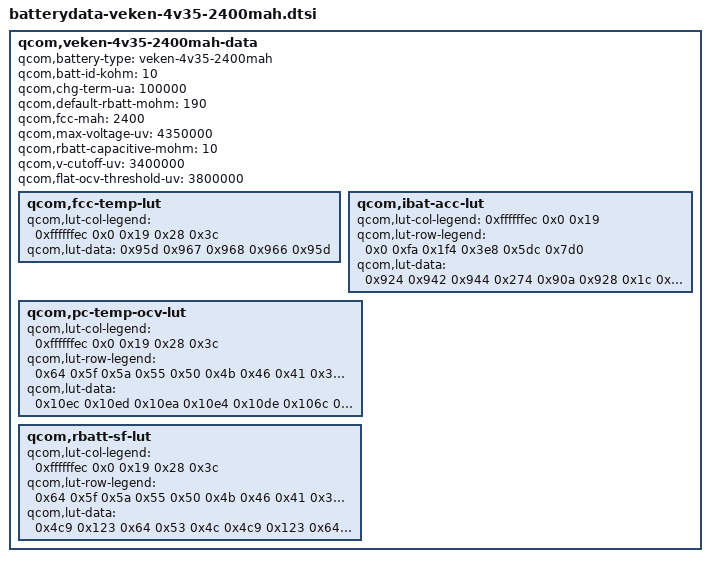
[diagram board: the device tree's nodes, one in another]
/* Copyright (c) 2013, The Linux Foundation. All rights reserved.
 *
 * This program is free software; you can redistribute it and/or modify
 * it under the terms of the GNU General Public License version 2 and
 * only version 2 as published by the Free Software Foundation.
 *
 * This program is distributed in the hope that it will be useful,
 * but WITHOUT ANY WARRANTY; without even the implied warranty of
 * MERCHANTABILITY or FITNESS FOR A PARTICULAR PURPOSE.  See the
 * GNU General Public License for more details.
 */

qcom,veken-4v35-2400mah-data {
	qcom,battery-type = "veken-4v35-2400mah";
	qcom,batt-id-kohm = <10>;
	qcom,chg-term-ua = <100000>;
	qcom,default-rbatt-mohm = <190>;
	qcom,fcc-mah = <2400>;
	qcom,max-voltage-uv = <4350000>;
	qcom,rbatt-capacitive-mohm = <10>;
	qcom,v-cutoff-uv = <3400000>;
	qcom,flat-ocv-threshold-uv = <3800000>;

	qcom,fcc-temp-lut {
		qcom,lut-col-legend = <0xffffffec 0x0 0x19 0x28 0x3c>;
		qcom,lut-data = <0x95d 0x967 0x968 0x966 0x95d>;
	};

	qcom,ibat-acc-lut {
		qcom,lut-col-legend = <0xffffffec 0x0 0x19>;
		qcom,lut-row-legend = <0x0 0xfa 0x1f4 0x3e8 0x5dc 0x7d0>;
		qcom,lut-data = <0x924 0x942 0x944 0x274 0x90a 0x928 0x1c 0x824 0x914 0x2 0x4bc 0x8d7 0x0 0x2c2 0x7f0 0x1 0x196 0x600>;
	};

	qcom,pc-temp-ocv-lut {
		qcom,lut-col-legend = <0xffffffec 0x0 0x19 0x28 0x3c>;
		qcom,lut-row-legend = <0x64 0x5f 0x5a 0x55 0x50 0x4b 0x46 0x41 0x3c 0x37 0x32 0x2d 0x28 0x23 0x1e 0x19 0x14 0x10 0xd 0xb 0xa 0x9 0x8 0x7 0x6 0x5 0x4 0x3 0x2 0x1 0x0>;
		qcom,lut-data = <0x10ec 0x10ed 0x10ea 0x10e4 0x10de 0x106c 0x109a 0x10a4 0x10a2 0x109e 0x1022 0x105d 0x106a 0x106a 0x1066 0xfd4 0x1026 0x1036 0x1034 0x1032 0xf8c 0xff2 0x1000 0x1000 0xffe 0xf5a 0xfb8 0xfd5 0xfd0 0xfcc 0xf30 0xf73 0xf96 0xf9c 0xfa0 0xf12 0xf4f 0xf74 0xf78 0xf77 0xefb 0xf2d 0xf44 0xf4c 0xf4e 0xee8 0xf0d 0xf1c 0xf1c 0xf1d 0xed8 0xef2 0xeff 0xf00 0xf00 0xec8 0xedc 0xee8 0xee8 0xee8 0xeba 0xecc 0xed4 0xed5 0xed4 0xeac 0xebf 0xec4 0xec4 0xec4 0xe9c 0xeb4 0xeb6 0xeb3 0xeaf 0xe8b 0xea6 0xea7 0xea0 0xe95 0xe76 0xe94 0xe96 0xe8e 0xe81 0xe60 0xe84 0xe82 0xe7a 0xe6d 0xe4c 0xe76 0xe70 0xe67 0xe5a 0xe3c 0xe6e 0xe68 0xe60 0xe55 0xe35 0xe6a 0xe66 0xe5e 0xe53 0xe2c 0xe64 0xe64 0xe5c 0xe51 0xe1e 0xe5e 0xe61 0xe5a 0xe4e 0xe0e 0xe54 0xe5c 0xe55 0xe4a 0xdf8 0xe46 0xe52 0xe4c 0xe3e 0xddc 0xe2c 0xe3b 0xe33 0xe22 0xdb4 0xe04 0xe10 0xe06 0xdf4 0xd7a 0xdca 0xdd5 0xdca 0xdb8 0xd20 0xd76 0xd82 0xd76 0xd64 0xc8f 0xcf2 0xcf8 0xcec 0xcdc 0xbb8 0xbb8 0xbb8 0xbb8 0xbb8>;
	};

	qcom,rbatt-sf-lut {
		qcom,lut-col-legend = <0xffffffec 0x0 0x19 0x28 0x3c>;
		qcom,lut-row-legend = <0x64 0x5f 0x5a 0x55 0x50 0x4b 0x46 0x41 0x3c 0x37 0x32 0x2d 0x28 0x23 0x1e 0x19 0x14 0x10 0xd 0xb 0xa 0x9 0x8 0x7 0x6 0x5 0x4 0x3 0x2 0x1>;
		qcom,lut-data = <0x4c9 0x123 0x64 0x53 0x4c 0x4c9 0x123 0x64 0x53 0x4c 0x45b 0x11c 0x65 0x53 0x4d 0x400 0x117 0x66 0x55 0x4e 0x3b8 0x113 0x68 0x56 0x4f 0x397 0x10e 0x6d 0x59 0x50 0x386 0xfb 0x6d 0x5b 0x52 0x380 0xfb 0x72 0x5e 0x54 0x383 0xf5 0x68 0x5e 0x55 0x38d 0xf3 0x61 0x53 0x4e 0x39b 0xf4 0x61 0x52 0x4d 0x3ac 0xf6 0x62 0x53 0x4d 0x3c5 0xfb 0x61 0x54 0x4e 0x3e0 0x102 0x63 0x55 0x50 0x404 0x10d 0x63 0x54 0x4f 0x430 0x119 0x63 0x53 0x4d 0x46a 0x127 0x63 0x53 0x4e 0x4a3 0x137 0x65 0x55 0x4e 0x4de 0x14b 0x65 0x54 0x4d 0x511 0x15a 0x65 0x54 0x4e 0x519 0x15d 0x66 0x55 0x4f 0x557 0x168 0x67 0x56 0x51 0x5d5 0x177 0x6a 0x58 0x53 0x66d 0x188 0x6d 0x5b 0x55 0x72d 0x19b 0x70 0x5d 0x55 0x825 0x1af 0x6f 0x59 0x51 0x97a 0x1c8 0x6c 0x58 0x52 0xb6f 0x1ed 0x70 0x59 0x52 0xf0c 0x226 0x75 0x5b 0x53 0x1e17 0x3ac 0x90 0x72 0x66>;
	};
};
